# CH32H417 register map
Vendor: WCH Ltd.; File version: 1.2
Registers are 32-bit, read-write, reset 0x0 unless marked. A register's access mark holds for its fields unless they carry their own. Offsets are from the block's base; [hi:lo] are bit positions; 'fields as' and 'values as' point back to an identical list.

## LTDC — LCD-TFT Controller
Base 0x40014800
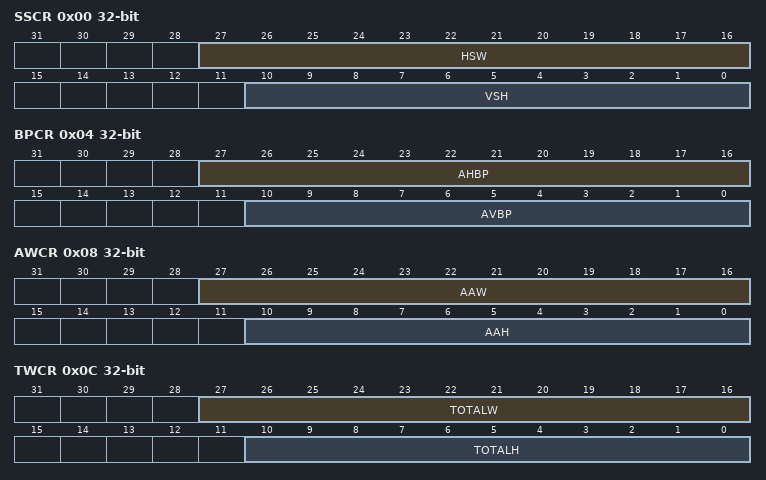
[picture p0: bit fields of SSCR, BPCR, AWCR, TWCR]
0x00 SSCR — Synchronization Size Configuration Register
  [27:16] HSW — Horizontal Synchronization Width (in units of pixel clock period)
  [10:0] VSH — Vertical Synchronization Height (in units of horizontal scan line)
0x04 BPCR — Back Porch Configuration Register
  [27:16] AHBP — Accumulated Horizontal back porch (in units of pixel clock period)
  [10:0] AVBP — Accumulated Vertical back porch (in units of horizontal scan line)
0x08 AWCR — Active Width Configuration Register
  [27:16] AAW — Accumulated Active Width (in units of pixel clock period)
  [10:0] AAH — Accumulated Active Height (in units of horizontal scan line)
0x0C TWCR — Total Width Configuration Register
  [27:16] TOTALW — Total Width (in units of pixel clock period)
  [10:0] TOTALH — Total Height (in units of horizontal scan line)
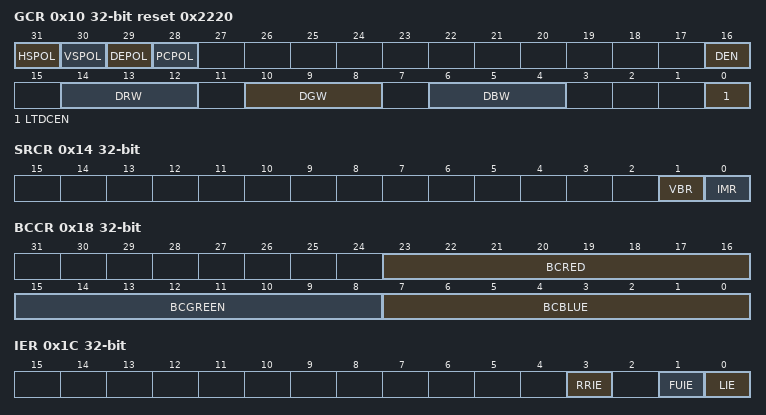
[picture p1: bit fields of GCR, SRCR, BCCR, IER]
0x10 GCR access per field reset 0x2220 — Global Control Register
  [31] HSPOL rw — Horizontal Synchronization Polarity
  [30] VSPOL rw — Vertical Synchronization Polarity
  [29] DEPOL rw — Data Enable Polarity
  [28] PCPOL rw — Pixel Clock Polarity
  [16] DEN rw — Dither Enable
  [14:12] DRW ro — Dither Red Width
  [10:8] DGW ro — Dither Green Width
  [6:4] DBW ro — Dither Blue Width
  [0] LTDCEN rw — LCD-TFT controller enable bit
0x14 SRCR — Shadow Reload Configuration Register
  [1] VBR — Vertical Blanking Reload
  [0] IMR — Immediate Reload
0x18 BCCR — Background Color Configuration Register
  [23:16] BCRED — Background Color Red value
  [15:8] BCGREEN — Background Color Green value
  [7:0] BCBLUE — Background Color Blue value
0x1C IER — Interrupt Enable Register
  [3] RRIE — Register Reload interrupt enable
  [1] FUIE — FIFO Underrun Interrupt Enable
  [0] LIE — Line Interrupt Enable
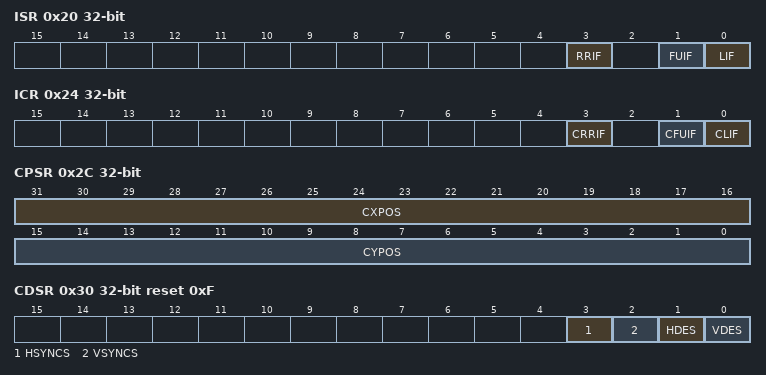
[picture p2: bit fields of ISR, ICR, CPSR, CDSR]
0x20 ISR ro — Interrupt Status Register
  [3] RRIF — Register Reload Interrupt Flag
  [1] FUIF — FIFO Underrun Interrupt flag
  [0] LIF — Line Interrupt flag
0x24 ICR wo — Interrupt Clear Register
  [3] CRRIF — Clears Register Reload Interrupt Flag
  [1] CFUIF — Clears the FIFO Underrun Interrupt flag
  [0] CLIF — Clears the Line Interrupt Flag
0x28 LIPCR — Line Interrupt Position Configuration Register
  [10:0] LIPOS — Line Interrupt Position
0x2C CPSR — Current Position Status Register
  [31:16] CXPOS — Current X Position
  [15:0] CYPOS — Current Y Position
0x30 CDSR ro reset 0xF — Current Display Status Register
  [3] HSYNCS — Horizontal Synchronization display Status
  [2] VSYNCS — Vertical Synchronization display Status
  [1] HDES — Horizontal Data Enable display Status
  [0] VDES — Vertical Data Enable display Status
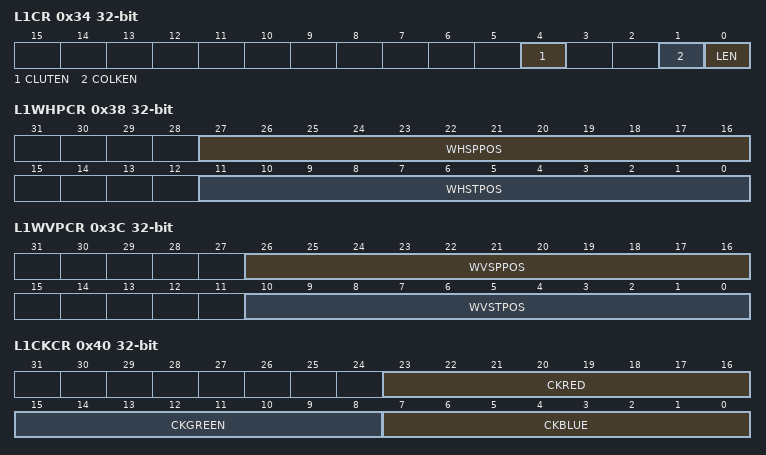
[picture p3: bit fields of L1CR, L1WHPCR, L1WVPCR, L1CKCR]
0x34 L1CR — Layerx Control Register
  [4] CLUTEN — Color Look-Up Table Enable
  [1] COLKEN — Color Keying Enable
  [0] LEN — Layer Enable
0x38 L1WHPCR — Layerx Window Horizontal Position Configuration Register
  [27:16] WHSPPOS — Window Horizontal Stop Position
  [11:0] WHSTPOS — Window Horizontal Start Position
0x3C L1WVPCR — Layerx Window Vertical Position Configuration Register
  [26:16] WVSPPOS — Window Vertical Stop Position
  [10:0] WVSTPOS — Window Vertical Start Position
0x40 L1CKCR — Layerx Color Keying Configuration Register
  [23:16] CKRED — Color Key Red value
  [15:8] CKGREEN — Color Key Green value
  [7:0] CKBLUE — Color Key Blue value
0x44 L1PFCR — Layerx Pixel Format Configuration Register
  [2:0] PF — Pixel Format
0x48 L1CACR — Layerx Constant Alpha Configuration Register
  [7:0] CONSTA — Constant Alpha
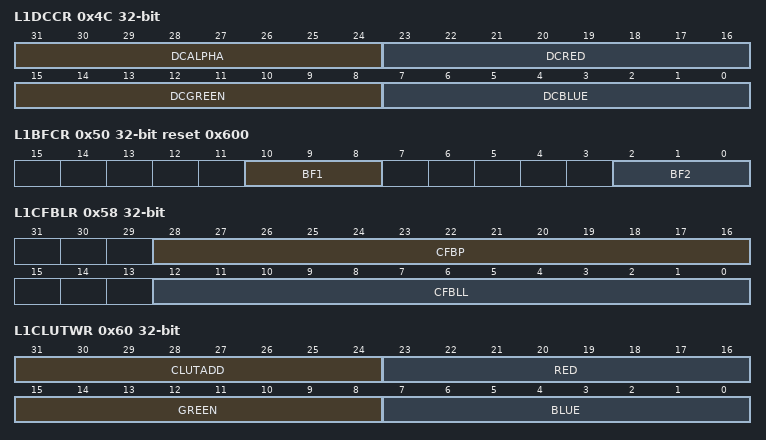
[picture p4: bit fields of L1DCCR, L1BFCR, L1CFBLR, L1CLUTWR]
0x4C L1DCCR — Layerx Default Color Configuration Register
  [31:24] DCALPHA — Default Color Alpha
  [23:16] DCRED — Default Color Red
  [15:8] DCGREEN — Default Color Green
  [7:0] DCBLUE — Default Color Blue
0x50 L1BFCR reset 0x600 — Layerx Blending Factors Configuration Register
  [10:8] BF1 — Blending Factor 1
  [2:0] BF2 — Blending Factor 2
0x54 L1CFBAR — Layerx Color Frame Buffer Address Register
  [31:0] CFBADD — Color Frame Buffer Start Address
0x58 L1CFBLR — Layerx Color Frame Buffer Length Register
  [28:16] CFBP — Color Frame Buffer Pitch in bytes
  [12:0] CFBLL — Color Frame Buffer Line Length
0x5C L1CFBLNR — Layerx ColorFrame Buffer Line Number Register
  [10:0] CFBLNBR — Frame Buffer Line Number
0x60 L1CLUTWR wo — Layerx CLUT Write Register
  [31:24] CLUTADD — CLUT Address
  [23:16] RED — Red value
  [15:8] GREEN — Green value
  [7:0] BLUE — Blue value
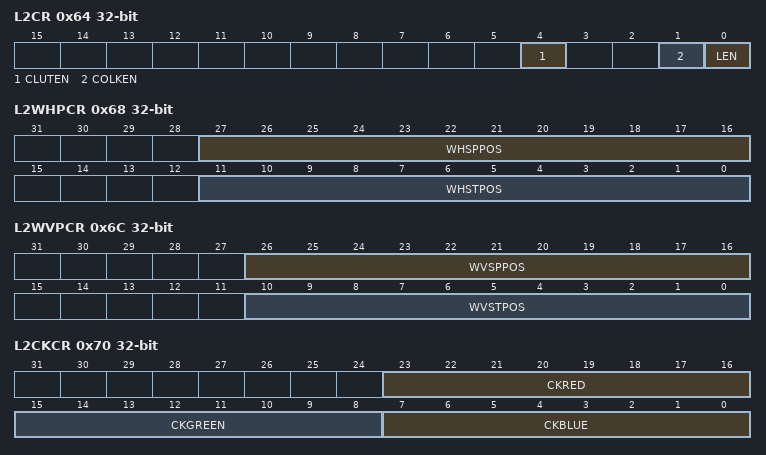
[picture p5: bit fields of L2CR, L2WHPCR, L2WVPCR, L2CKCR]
0x64 L2CR — Layerx Control Register
  fields as L1CR
0x68 L2WHPCR — Layerx Window Horizontal Position Configuration Register
  fields as L1WHPCR
0x6C L2WVPCR — Layerx Window Vertical Position Configuration Register
  fields as L1WVPCR
0x70 L2CKCR — Layerx Color Keying Configuration Register
  fields as L1CKCR
0x74 L2PFCR — Layerx Pixel Format Configuration Register
  [2:0] PF — Pixel Format
0x78 L2CACR — Layerx Constant Alpha Configuration Register
  [7:0] CONSTA — Constant Alpha
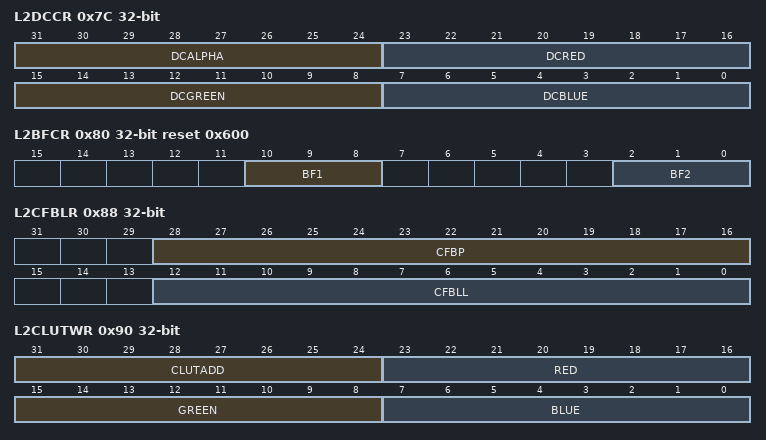
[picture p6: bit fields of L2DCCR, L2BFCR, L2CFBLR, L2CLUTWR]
0x7C L2DCCR — Layerx Default Color Configuration Register
  fields as L1DCCR
0x80 L2BFCR reset 0x600 — Layerx Blending Factors Configuration Register
  [10:8] BF1 — Blending Factor 1
  [2:0] BF2 — Blending Factor 2
0x84 L2CFBAR — Layerx Color Frame Buffer Address Register
  [31:0] CFBADD — Color Frame Buffer Start Address
0x88 L2CFBLR — Layerx Color Frame Buffer Length Register
  fields as L1CFBLR
0x8C L2CFBLNR — Layerx ColorFrame Buffer Line Number Register
  [10:0] CFBLNBR — Frame Buffer Line Number
0x90 L2CLUTWR wo — Layerx CLUT Write Register
  fields as L1CLUTWR
